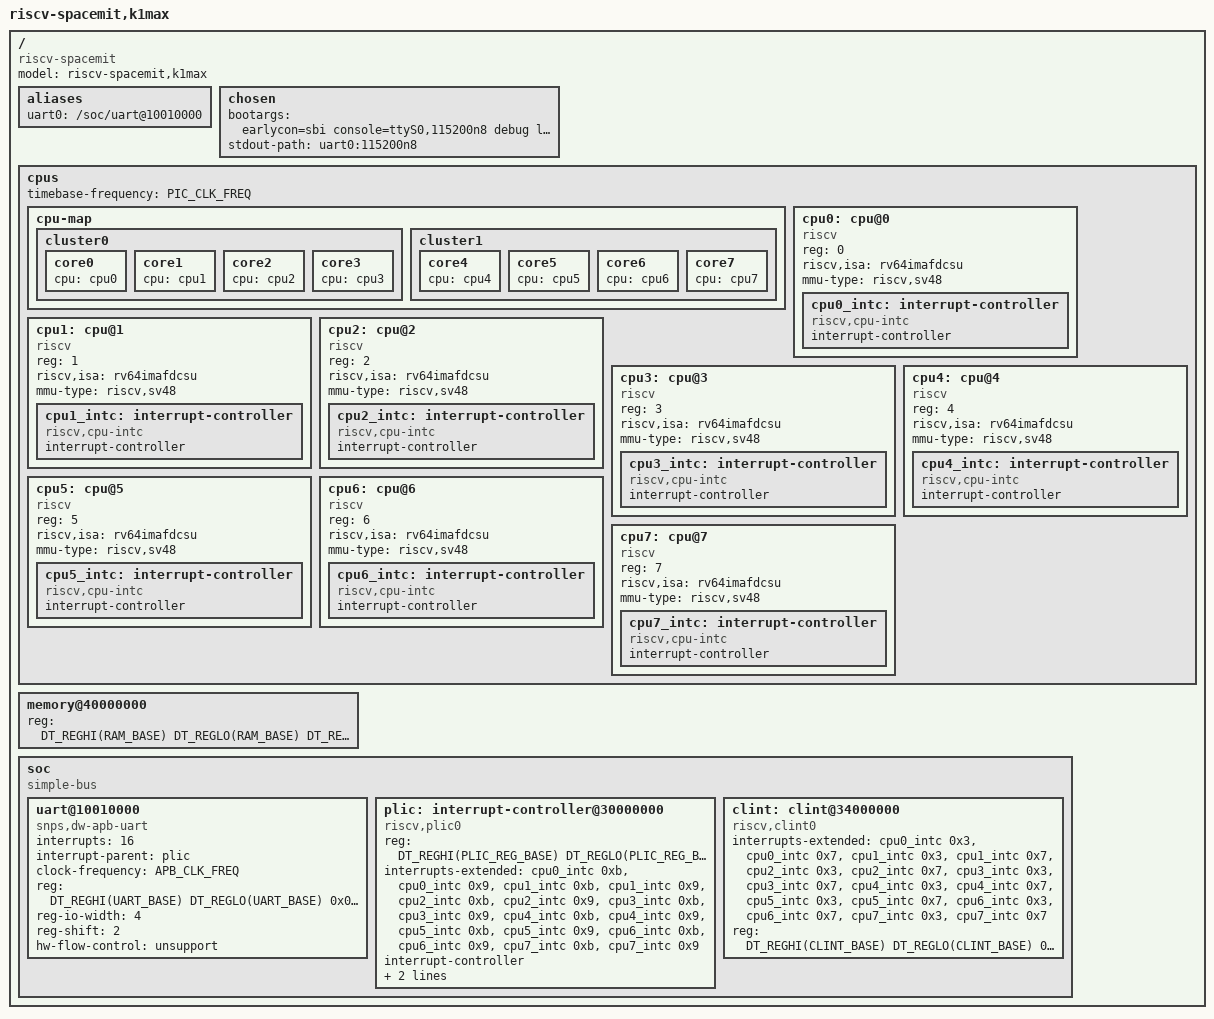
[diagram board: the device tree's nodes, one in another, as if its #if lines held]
#include <target/arch.h>
#include <dt-bindings/clock/sbi-clock-k1max.h>

/dts-v1/;

/memreserve/ RAM_BASE 0x02000000;

/ {
	#address-cells = <0x2>;
	#size-cells = <0x2>;
	compatible = "riscv-spacemit";
	model = "riscv-spacemit,k1max";

	aliases {
		uart0 = "/soc/uart@10010000";
	};

	chosen {
#ifdef CONFIG_K1M_UART_DTS_CON
		bootargs = "earlycon=sbi console=ttyS0,115200n8 debug loglevel=8,initcall_debug=1 rdinit=/sdfirm_init";
		stdout-path = "uart0:115200n8";
#else
		bootargs = "console=hvc0 earlycon=sbi rdinit=/sdfirm_init";
#endif
	};

	cpus {
		#address-cells = <0x1>;
		#size-cells = <0x0>;
		timebase-frequency = <PIC_CLK_FREQ>;

		cpu-map {
			cluster0 {
				core0 {
					cpu = <&cpu0>;
				};
#ifdef CONFIG_SMP
				core1 {
					cpu = <&cpu1>;
				};
#endif
#if CONFIG_K1M_SMP_CPUS >= 4
				core2 {
					cpu = <&cpu2>;
				};
				core3 {
					cpu = <&cpu3>;
				};
#endif
			};
#if CONFIG_K1M_SMP_CPUS >= 8
			cluster1 {
				core4 {
					cpu = <&cpu4>;
				};
				core5 {
					cpu = <&cpu5>;
				};
				core6 {
					cpu = <&cpu6>;
				};
				core7 {
					cpu = <&cpu7>;
				};
			};
#endif
		};

		cpu0: cpu@0 {
			device_type = "cpu";
			reg = <0>;
			status = "okay";
			compatible = "riscv";
			riscv,isa = "rv64imafdcsu";
			mmu-type = "riscv,sv48";

			cpu0_intc: interrupt-controller {
				#interrupt-cells = <0x1>;
				interrupt-controller;
				compatible = "riscv,cpu-intc";
			};
		};
#ifdef CONFIG_SMP
		cpu1: cpu@1 {
			device_type = "cpu";
			reg = <1>;
			status = "okay";
			compatible = "riscv";
			riscv,isa = "rv64imafdcsu";
			mmu-type = "riscv,sv48";

			cpu1_intc: interrupt-controller {
				#interrupt-cells = <0x1>;
				interrupt-controller;
				compatible = "riscv,cpu-intc";
			};
		};
#endif
#if CONFIG_K1M_SMP_CPUS >= 4
		cpu2: cpu@2 {
			device_type = "cpu";
			reg = <2>;
			status = "okay";
			compatible = "riscv";
			riscv,isa = "rv64imafdcsu";
			mmu-type = "riscv,sv48";

			cpu2_intc: interrupt-controller {
				#interrupt-cells = <0x1>;
				interrupt-controller;
				compatible = "riscv,cpu-intc";
			};
		};
		cpu3: cpu@3 {
			device_type = "cpu";
			reg = <3>;
			status = "okay";
			compatible = "riscv";
			riscv,isa = "rv64imafdcsu";
			mmu-type = "riscv,sv48";

			cpu3_intc: interrupt-controller {
				#interrupt-cells = <0x1>;
				interrupt-controller;
				compatible = "riscv,cpu-intc";
			};
		};
#endif
#if CONFIG_K1M_SMP_CPUS >= 8
		cpu4: cpu@4 {
			device_type = "cpu";
			reg = <4>;
			status = "okay";
			compatible = "riscv";
			riscv,isa = "rv64imafdcsu";
			mmu-type = "riscv,sv48";

			cpu4_intc: interrupt-controller {
				#interrupt-cells = <0x1>;
				interrupt-controller;
				compatible = "riscv,cpu-intc";
			};
		};
		cpu5: cpu@5 {
			device_type = "cpu";
			reg = <5>;
			status = "okay";
			compatible = "riscv";
			riscv,isa = "rv64imafdcsu";
			mmu-type = "riscv,sv48";

			cpu5_intc: interrupt-controller {
				#interrupt-cells = <0x1>;
				interrupt-controller;
				compatible = "riscv,cpu-intc";
			};
		};
		cpu6: cpu@6 {
			device_type = "cpu";
			reg = <6>;
			status = "okay";
			compatible = "riscv";
			riscv,isa = "rv64imafdcsu";
			mmu-type = "riscv,sv48";

			cpu6_intc: interrupt-controller {
				#interrupt-cells = <0x1>;
				interrupt-controller;
				compatible = "riscv,cpu-intc";
			};
		};
		cpu7: cpu@7 {
			device_type = "cpu";
			reg = <7>;
			status = "okay";
			compatible = "riscv";
			riscv,isa = "rv64imafdcsu";
			mmu-type = "riscv,sv48";

			cpu7_intc: interrupt-controller {
				#interrupt-cells = <0x1>;
				interrupt-controller;
				compatible = "riscv,cpu-intc";
			};
		};
#endif
	};

	memory@40000000 {
		device_type = "memory";
		reg = <DT_REGHI(RAM_BASE) DT_REGLO(RAM_BASE)
		       DT_REGHI(RAM_SIZE) DT_REGLO(RAM_SIZE)
		>;
	};

	soc {
		#address-cells = <0x2>;
		#size-cells = <0x2>;
		compatible = "simple-bus";
		ranges;

		uart@10010000 {
			interrupts = <16>;
			interrupt-parent = <&plic>;
			clock-frequency = <APB_CLK_FREQ>;
			reg = <DT_REGHI(UART_BASE) DT_REGLO(UART_BASE)
			       0x0 0x1000
			>;
			reg-io-width = <4>;
			reg-shift = <2>;
			hw-flow-control = "unsupport";
			compatible = "snps,dw-apb-uart";
#ifdef CONFIG_K1M_UART_DTS_CON
			status = "okay";
#else
			status = "disabled";
#endif
		};

		plic: interrupt-controller@30000000 {
			reg = <DT_REGHI(PLIC_REG_BASE) DT_REGLO(PLIC_REG_BASE)
			       0x0 0x08000000
			>;
			interrupts-extended = <
				&cpu0_intc 0xb &cpu0_intc 0x9
#ifdef CONFIG_SMP
				&cpu1_intc 0xb &cpu1_intc 0x9
#endif
#if CONFIG_K1M_SMP_CPUS >= 4
				&cpu2_intc 0xb &cpu2_intc 0x9
				&cpu3_intc 0xb &cpu3_intc 0x9
#endif
#if CONFIG_K1M_SMP_CPUS >= 8
				&cpu4_intc 0xb &cpu4_intc 0x9
				&cpu5_intc 0xb &cpu5_intc 0x9
				&cpu6_intc 0xb &cpu6_intc 0x9
				&cpu7_intc 0xb &cpu7_intc 0x9
#endif
			>;
			interrupt-controller;
			riscv,ndev = <160>;
			riscv,max-priority = <7>;
			compatible = "riscv,plic0";
			#interrupt-cells = <0x1>;
			#address-cells = <0x0>;
		};

		clint: clint@34000000 {
			interrupts-extended = <
				&cpu0_intc 0x3 &cpu0_intc 0x7
#ifdef CONFIG_SMP
				&cpu1_intc 0x3 &cpu1_intc 0x7
#endif
#if CONFIG_K1M_SMP_CPUS >= 4
				&cpu2_intc 0x3 &cpu2_intc 0x7
				&cpu3_intc 0x3 &cpu3_intc 0x7
#endif
#if CONFIG_K1M_SMP_CPUS >= 8
				&cpu4_intc 0x3 &cpu4_intc 0x7
				&cpu5_intc 0x3 &cpu5_intc 0x7
				&cpu6_intc 0x3 &cpu6_intc 0x7
				&cpu7_intc 0x3 &cpu7_intc 0x7
#endif
			>;
			reg = <DT_REGHI(CLINT_BASE) DT_REGLO(CLINT_BASE)
			       0x0 0x00010000
			>;
			compatible = "riscv,clint0";
		};
	};
};
